AUTOSAR XML (schema 4-2-2)
package /STELLANTIS/EPT/ASWCs
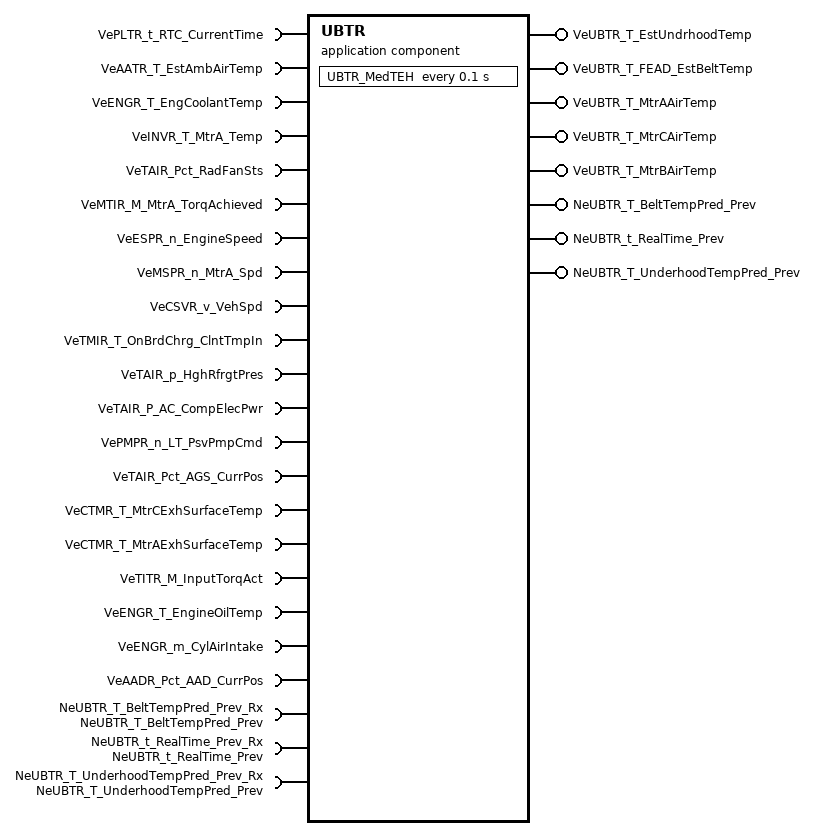
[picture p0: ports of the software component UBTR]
  application sw component type UBTR
    20 x require port, all with nonqueued-receiver-com-spec{data-element=Value, init-value=0}:
      VePLTR_t_RTC_CurrentTime: variation-point={short-label=vpVePLTR_t_RTC_CurrentTime, sw-syscond=1}, required-interface=VePLTR_t_RTC_CurrentTime
      VeAATR_T_EstAmbAirTemp: variation-point={short-label=vpVeAATR_T_EstAmbAirTemp, sw-syscond=1}, required-interface=VeAATR_T_EstAmbAirTemp
      VeENGR_T_EngCoolantTemp: variation-point={short-label=vpVeENGR_T_EngCoolantTemp, sw-syscond=1}, required-interface=VeENGR_T_EngCoolantTemp
      VeINVR_T_MtrA_Temp: variation-point={short-label=vpVeINVR_T_MtrA_Temp, sw-syscond=1}, required-interface=VeINVR_T_MtrA_Temp
      VeTAIR_Pct_RadFanSts: variation-point={short-label=vpVeTAIR_Pct_RadFanSts, sw-syscond=1}, required-interface=VeTAIR_Pct_RadFanSts
      VeMTIR_M_MtrA_TorqAchieved: variation-point={short-label=vpVeMTIR_M_MtrA_TorqAchieved, sw-syscond=1}, required-interface=VeMTIR_M_MtrA_TorqAchieved
      VeESPR_n_EngineSpeed: variation-point={short-label=vpVeESPR_n_EngineSpeed, sw-syscond=1}, required-interface=VeESPR_n_EngineSpeed
      VeMSPR_n_MtrA_Spd: variation-point={short-label=vpVeMSPR_n_MtrA_Spd, sw-syscond=1}, required-interface=VeMSPR_n_MtrA_Spd
      VeCSVR_v_VehSpd: variation-point={short-label=vpVeCSVR_v_VehSpd, sw-syscond=1}, required-interface=VeCSVR_v_VehSpd
      VeTMIR_T_OnBrdChrg_ClntTmpIn: variation-point={short-label=vpVeTMIR_T_OnBrdChrg_ClntTmpIn, sw-syscond=1}, required-interface=VeTMIR_T_OnBrdChrg_ClntTmpIn
      VeTAIR_p_HghRfrgtPres: variation-point={short-label=vpVeTAIR_p_HghRfrgtPres, sw-syscond=1}, required-interface=VeTAIR_p_HghRfrgtPres
      VeTAIR_P_AC_CompElecPwr: variation-point={short-label=vpVeTAIR_P_AC_CompElecPwr, sw-syscond=1}, required-interface=VeTAIR_P_AC_CompElecPwr
      VePMPR_n_LT_PsvPmpCmd: variation-point={short-label=vpVePMPR_n_LT_PsvPmpCmd, sw-syscond=1}, required-interface=VePMPR_n_LT_PsvPmpCmd
      VeTAIR_Pct_AGS_CurrPos: variation-point={short-label=vpVeTAIR_Pct_AGS_CurrPos, sw-syscond=1}, required-interface=VeTAIR_Pct_AGS_CurrPos
      VeCTMR_T_MtrCExhSurfaceTemp: variation-point={short-label=vpVeCTMR_T_MtrCExhSurfaceTemp, sw-syscond=1}, required-interface=VeCTMR_T_MtrCExhSurfaceTemp
      VeCTMR_T_MtrAExhSurfaceTemp: variation-point={short-label=vpVeCTMR_T_MtrAExhSurfaceTemp, sw-syscond=1}, required-interface=VeCTMR_T_MtrAExhSurfaceTemp
      VeTITR_M_InputTorqAct: variation-point={short-label=vpVeTITR_M_InputTorqAct, sw-syscond=1}, required-interface=VeTITR_M_InputTorqAct
      VeENGR_T_EngineOilTemp: variation-point={short-label=vpVeENGR_T_EngineOilTemp, sw-syscond=1}, required-interface=VeENGR_T_EngineOilTemp
      VeENGR_m_CylAirIntake: variation-point={short-label=vpVeENGR_m_CylAirIntake, sw-syscond=1}, required-interface=VeENGR_m_CylAirIntake
      VeAADR_Pct_AAD_CurrPos: variation-point={short-label=vpVeAADR_Pct_AAD_CurrPos, sw-syscond=1}, required-interface=VeAADR_Pct_AAD_CurrPos
    5 x provide port, all with nonqueued-sender-com-spec{data-element=Value, init-value=0}:
      VeUBTR_T_EstUndrhoodTemp: variation-point={short-label=vpVeUBTR_T_EstUndrhoodTemp, sw-syscond=1}, provided-interface=VeUBTR_T_EstUndrhoodTemp
      VeUBTR_T_FEAD_EstBeltTemp: variation-point={short-label=vpVeUBTR_T_FEAD_EstBeltTemp, sw-syscond=1}, provided-interface=VeUBTR_T_FEAD_EstBeltTemp
      VeUBTR_T_MtrAAirTemp: variation-point={short-label=vpVeUBTR_T_MtrAAirTemp, sw-syscond=1}, provided-interface=VeUBTR_T_MtrAAirTemp
      VeUBTR_T_MtrCAirTemp: variation-point={short-label=vpVeUBTR_T_MtrCAirTemp, sw-syscond=1}, provided-interface=VeUBTR_T_MtrCAirTemp
      VeUBTR_T_MtrBAirTemp: variation-point={short-label=vpVeUBTR_T_MtrBAirTemp, sw-syscond=1}, provided-interface=VeUBTR_T_MtrBAirTemp
    require port NeUBTR_T_BeltTempPred_Prev_Rx: nv-require-com-spec{init-value=-10, variable=NeUBTR_T_BeltTempPred_Prev}, required-interface=NeUBTR_T_BeltTempPred_Prev
    require port NeUBTR_t_RealTime_Prev_Rx: nv-require-com-spec{init-value=0, variable=NeUBTR_t_RealTime_Prev}, required-interface=NeUBTR_t_RealTime_Prev
    require port NeUBTR_T_UnderhoodTempPred_Prev_Rx: nv-require-com-spec{init-value=-10, variable=NeUBTR_T_UnderhoodTempPred_Prev}, required-interface=NeUBTR_T_UnderhoodTempPred_Prev
    provide port NeUBTR_T_BeltTempPred_Prev: nv-provide-com-spec{ram-block-init-value=-10, variable=NeUBTR_T_BeltTempPred_Prev}, provided-interface=NeUBTR_T_BeltTempPred_Prev
    provide port NeUBTR_t_RealTime_Prev: nv-provide-com-spec{ram-block-init-value=0, variable=NeUBTR_t_RealTime_Prev}, provided-interface=NeUBTR_t_RealTime_Prev
    provide port NeUBTR_T_UnderhoodTempPred_Prev: nv-provide-com-spec{ram-block-init-value=-10, variable=NeUBTR_T_UnderhoodTempPred_Prev}, provided-interface=NeUBTR_T_UnderhoodTempPred_Prev
    behavior IB_UBTR: data-type-mapping=msADTtoIDTMapping, handle-termination-and-restart=NO-SUPPORT
      timing event Event_MedTEH: start-on-event=UBTR_MedTEH, period=0.1
      init event Event_UBTR_ac_Init: start-on-event=UBTR_ac_Init
      init event Event_PwrOn: start-on-event=UBTR_PwrOn
      init event Event_PwrOff: start-on-event=UBTR_PwrOff
      explicit-inter-runnable-variables:
        data RealTime_Saved_write_IRV: category=VALUE, sw-calibration-access=READ-ONLY, type=UInt32, init-value=0, variation-point={short-label=vpRealTime_Saved_write_IRV, sw-syscond=1}
        data BeltTempSaved_write_IRV: category=VALUE, sw-calibration-access=READ-ONLY, type=Float, init-value=0, variation-point={short-label=vpBeltTempSaved_write_IRV, sw-syscond=1}
        data UnderhoodTempSaved_write_IRV: category=VALUE, sw-calibration-access=READ-ONLY, type=Float, init-value=0, variation-point={short-label=vpUnderhoodTempSaved_write_IRV, sw-syscond=1}
      4 x runnable:
        UBTR_ac_Init
          written-local-variables:
            access WV_BeltTempSaved_write_IRV: accessed-variable=BeltTempSaved_write_IRV, variation-point={short-label=vpWV_BeltTempSaved_write_IRV, sw-syscond=1}
            access WV_RealTime_Saved_write_IRV: accessed-variable=RealTime_Saved_write_IRV, variation-point={short-label=vpWV_RealTime_Saved_write_IRV, sw-syscond=1}
            access WV_UnderhoodTempSaved_write_IRV: accessed-variable=UnderhoodTempSaved_write_IRV, variation-point={short-label=vpWV_UnderhoodTempSaved_write_IRV, sw-syscond=1}
        UBTR_PwrOn
          data-receive-point-by-arguments:
            access IN_NeUBTR_T_BeltTempPred_Prev_Rx_NeUBTR_T_BeltTempPred_Prev: accessed-variable=NeUBTR_T_BeltTempPred_Prev_Rx.NeUBTR_T_BeltTempPred_Prev
            access IN_NeUBTR_T_UnderhoodTempPred_Prev_Rx_NeUBTR_T_UnderhoodTempPred_Prev: accessed-variable=NeUBTR_T_UnderhoodTempPred_Prev_Rx.NeUBTR_T_UnderhoodTempPred_Prev
            access IN_NeUBTR_t_RealTime_Prev_Rx_NeUBTR_t_RealTime_Prev: accessed-variable=NeUBTR_t_RealTime_Prev_Rx.NeUBTR_t_RealTime_Prev
          data-send-points:
            5 x access:
              OUT_VeUBTR_T_EstUndrhoodTemp_Value: accessed-variable=VeUBTR_T_EstUndrhoodTemp.Value, variation-point={short-label=vpOUT_VeUBTR_T_EstUndrhoodTemp_Value, sw-syscond=1}
              OUT_VeUBTR_T_FEAD_EstBeltTemp_Value: accessed-variable=VeUBTR_T_FEAD_EstBeltTemp.Value, variation-point={short-label=vpOUT_VeUBTR_T_FEAD_EstBeltTemp_Value, sw-syscond=1}
              OUT_VeUBTR_T_MtrAAirTemp_Value: accessed-variable=VeUBTR_T_MtrAAirTemp.Value, variation-point={short-label=vpOUT_VeUBTR_T_MtrAAirTemp_Value, sw-syscond=1}
              OUT_VeUBTR_T_MtrCAirTemp_Value: accessed-variable=VeUBTR_T_MtrCAirTemp.Value, variation-point={short-label=vpOUT_VeUBTR_T_MtrCAirTemp_Value, sw-syscond=1}
              OUT_VeUBTR_T_MtrBAirTemp_Value: accessed-variable=VeUBTR_T_MtrBAirTemp.Value, variation-point={short-label=vpOUT_VeUBTR_T_MtrBAirTemp_Value, sw-syscond=1}
          written-local-variables:
            access WV_BeltTempSaved_write_IRV: accessed-variable=BeltTempSaved_write_IRV, variation-point={short-label=vpWV_BeltTempSaved_write_IRV, sw-syscond=1}
            access WV_RealTime_Saved_write_IRV: accessed-variable=RealTime_Saved_write_IRV, variation-point={short-label=vpWV_RealTime_Saved_write_IRV, sw-syscond=1}
            access WV_UnderhoodTempSaved_write_IRV: accessed-variable=UnderhoodTempSaved_write_IRV, variation-point={short-label=vpWV_UnderhoodTempSaved_write_IRV, sw-syscond=1}
        UBTR_MedTEH: variation-point={short-label=vpUBTR_MedTEH, sw-syscond=1}
          data-receive-point-by-arguments:
            20 x access:
              IN_VeAADR_Pct_AAD_CurrPos_Value: accessed-variable=VeAADR_Pct_AAD_CurrPos.Value, variation-point={short-label=vpIN_VeAADR_Pct_AAD_CurrPos_Value, sw-syscond=1}
              IN_VeAATR_T_EstAmbAirTemp_Value: accessed-variable=VeAATR_T_EstAmbAirTemp.Value, variation-point={short-label=vpIN_VeAATR_T_EstAmbAirTemp_Value, sw-syscond=1}
              IN_VeCSVR_v_VehSpd_Value: accessed-variable=VeCSVR_v_VehSpd.Value, variation-point={short-label=vpIN_VeCSVR_v_VehSpd_Value, sw-syscond=1}
              IN_VeCTMR_T_MtrAExhSurfaceTemp_Value: accessed-variable=VeCTMR_T_MtrAExhSurfaceTemp.Value, variation-point={short-label=vpIN_VeCTMR_T_MtrAExhSurfaceTemp_Value, sw-syscond=1}
              IN_VeCTMR_T_MtrCExhSurfaceTemp_Value: accessed-variable=VeCTMR_T_MtrCExhSurfaceTemp.Value, variation-point={short-label=vpIN_VeCTMR_T_MtrCExhSurfaceTemp_Value, sw-syscond=1}
              IN_VeENGR_T_EngCoolantTemp_Value: accessed-variable=VeENGR_T_EngCoolantTemp.Value, variation-point={short-label=vpIN_VeENGR_T_EngCoolantTemp_Value, sw-syscond=1}
              IN_VeENGR_T_EngineOilTemp_Value: accessed-variable=VeENGR_T_EngineOilTemp.Value, variation-point={short-label=vpIN_VeENGR_T_EngineOilTemp_Value, sw-syscond=1}
              IN_VeENGR_m_CylAirIntake_Value: accessed-variable=VeENGR_m_CylAirIntake.Value, variation-point={short-label=vpIN_VeENGR_m_CylAirIntake_Value, sw-syscond=1}
              IN_VeESPR_n_EngineSpeed_Value: accessed-variable=VeESPR_n_EngineSpeed.Value, variation-point={short-label=vpIN_VeESPR_n_EngineSpeed_Value, sw-syscond=1}
              IN_VeINVR_T_MtrA_Temp_Value: accessed-variable=VeINVR_T_MtrA_Temp.Value, variation-point={short-label=vpIN_VeINVR_T_MtrA_Temp_Value, sw-syscond=1}
              IN_VeMSPR_n_MtrA_Spd_Value: accessed-variable=VeMSPR_n_MtrA_Spd.Value, variation-point={short-label=vpIN_VeMSPR_n_MtrA_Spd_Value, sw-syscond=1}
              IN_VeMTIR_M_MtrA_TorqAchieved_Value: accessed-variable=VeMTIR_M_MtrA_TorqAchieved.Value, variation-point={short-label=vpIN_VeMTIR_M_MtrA_TorqAchieved_Value, sw-syscond=1}
              IN_VePLTR_t_RTC_CurrentTime_Value: accessed-variable=VePLTR_t_RTC_CurrentTime.Value, variation-point={short-label=vpIN_VePLTR_t_RTC_CurrentTime_Value, sw-syscond=1}
              IN_VePMPR_n_LT_PsvPmpCmd_Value: accessed-variable=VePMPR_n_LT_PsvPmpCmd.Value, variation-point={short-label=vpIN_VePMPR_n_LT_PsvPmpCmd_Value, sw-syscond=1}
              IN_VeTAIR_P_AC_CompElecPwr_Value: accessed-variable=VeTAIR_P_AC_CompElecPwr.Value, variation-point={short-label=vpIN_VeTAIR_P_AC_CompElecPwr_Value, sw-syscond=1}
              IN_VeTAIR_Pct_AGS_CurrPos_Value: accessed-variable=VeTAIR_Pct_AGS_CurrPos.Value, variation-point={short-label=vpIN_VeTAIR_Pct_AGS_CurrPos_Value, sw-syscond=1}
              IN_VeTAIR_Pct_RadFanSts_Value: accessed-variable=VeTAIR_Pct_RadFanSts.Value, variation-point={short-label=vpIN_VeTAIR_Pct_RadFanSts_Value, sw-syscond=1}
              IN_VeTAIR_p_HghRfrgtPres_Value: accessed-variable=VeTAIR_p_HghRfrgtPres.Value, variation-point={short-label=vpIN_VeTAIR_p_HghRfrgtPres_Value, sw-syscond=1}
              IN_VeTITR_M_InputTorqAct_Value: accessed-variable=VeTITR_M_InputTorqAct.Value, variation-point={short-label=vpIN_VeTITR_M_InputTorqAct_Value, sw-syscond=1}
              IN_VeTMIR_T_OnBrdChrg_ClntTmpIn_Value: accessed-variable=VeTMIR_T_OnBrdChrg_ClntTmpIn.Value, variation-point={short-label=vpIN_VeTMIR_T_OnBrdChrg_ClntTmpIn_Value, sw-syscond=1}
          data-send-points:
            5 x access:
              OUT_VeUBTR_T_EstUndrhoodTemp_Value: accessed-variable=VeUBTR_T_EstUndrhoodTemp.Value, variation-point={short-label=vpOUT_VeUBTR_T_EstUndrhoodTemp_Value, sw-syscond=1}
              OUT_VeUBTR_T_FEAD_EstBeltTemp_Value: accessed-variable=VeUBTR_T_FEAD_EstBeltTemp.Value, variation-point={short-label=vpOUT_VeUBTR_T_FEAD_EstBeltTemp_Value, sw-syscond=1}
              OUT_VeUBTR_T_MtrAAirTemp_Value: accessed-variable=VeUBTR_T_MtrAAirTemp.Value, variation-point={short-label=vpOUT_VeUBTR_T_MtrAAirTemp_Value, sw-syscond=1}
              OUT_VeUBTR_T_MtrCAirTemp_Value: accessed-variable=VeUBTR_T_MtrCAirTemp.Value, variation-point={short-label=vpOUT_VeUBTR_T_MtrCAirTemp_Value, sw-syscond=1}
              OUT_VeUBTR_T_MtrBAirTemp_Value: accessed-variable=VeUBTR_T_MtrBAirTemp.Value, variation-point={short-label=vpOUT_VeUBTR_T_MtrBAirTemp_Value, sw-syscond=1}
          read-local-variables:
            access RV_BeltTempSaved_write_IRV: accessed-variable=BeltTempSaved_write_IRV, variation-point={short-label=vpRV_BeltTempSaved_write_IRV, sw-syscond=1}
            access RV_RealTime_Saved_write_IRV: accessed-variable=RealTime_Saved_write_IRV, variation-point={short-label=vpRV_RealTime_Saved_write_IRV, sw-syscond=1}
            access RV_UnderhoodTempSaved_write_IRV: accessed-variable=UnderhoodTempSaved_write_IRV, variation-point={short-label=vpRV_UnderhoodTempSaved_write_IRV, sw-syscond=1}
        UBTR_PwrOff
          data-send-points:
            access OUT_NeUBTR_T_BeltTempPred_Prev_NeUBTR_T_BeltTempPred_Prev: accessed-variable=NeUBTR_T_BeltTempPred_Prev.NeUBTR_T_BeltTempPred_Prev
            access OUT_NeUBTR_t_RealTime_Prev_NeUBTR_t_RealTime_Prev: accessed-variable=NeUBTR_t_RealTime_Prev.NeUBTR_t_RealTime_Prev
            access OUT_NeUBTR_T_UnderhoodTempPred_Prev_NeUBTR_T_UnderhoodTempPred_Prev: accessed-variable=NeUBTR_T_UnderhoodTempPred_Prev.NeUBTR_T_UnderhoodTempPred_Prev
      5 x variation point proxy, all with category=CONDITION:
        Variant_UBTR_1: condition-access=1
        Variant_UBTR_3: condition-access=1
        Variant_UBTR_4: condition-access=0
        Variant_UBTR_5: condition-access=0
        Variant_UBTR_6: condition-access=1
